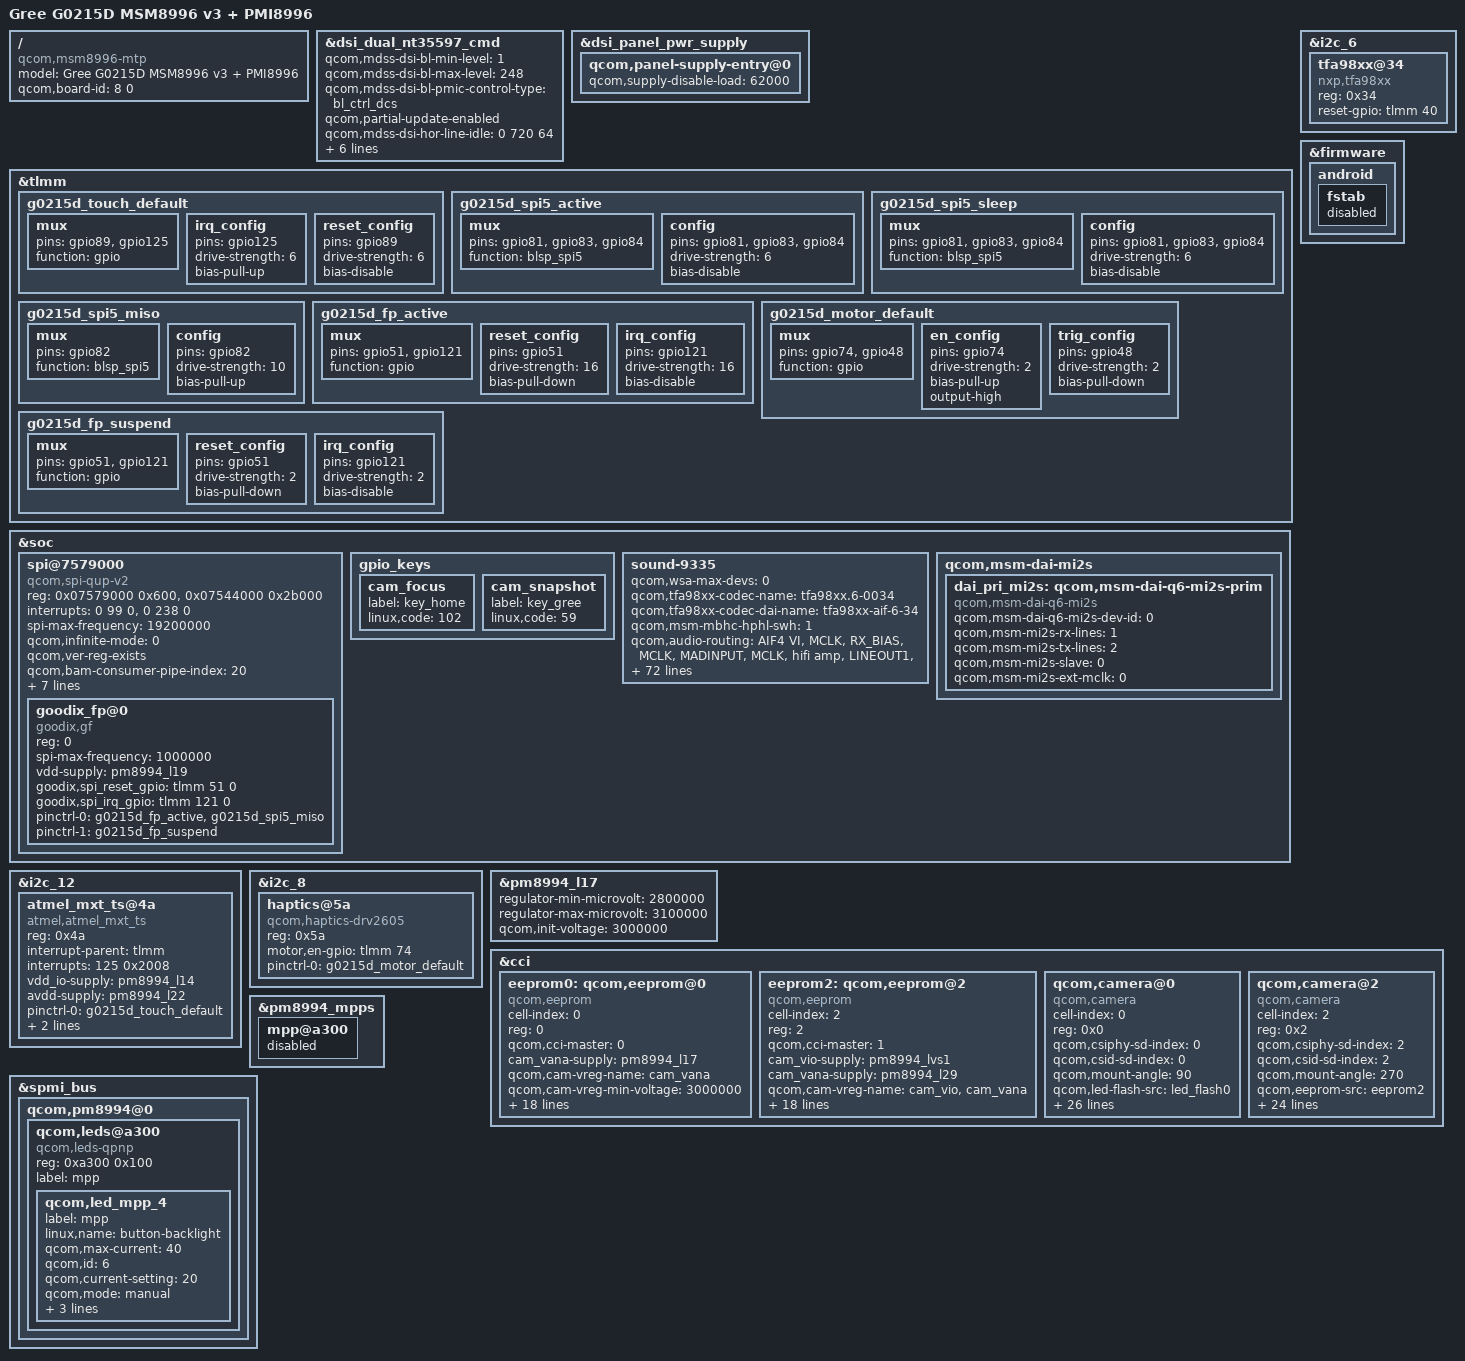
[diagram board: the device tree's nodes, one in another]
/* G0215D board. IDs match the bootloader on the running device:
 * msm-id 246 0x30001, board-id 8 0, pmic-id 0x20009 0x10013 0 0.
 * The bootloader appends the NT35597 config0 split_dsi panel selector.
 */

/dts-v1/;

#include "msm8996-v3.dtsi"
#include "msm-pmi8996.dtsi"
#include "msm8996-mtp.dtsi"

/ {
	model = "Gree G0215D MSM8996 v3 + PMI8996";
	compatible = "qcom,msm8996-mtp", "qcom,msm8996", "qcom,mtp";
	qcom,board-id = <8 0>;
};

&dsi_dual_nt35597_cmd {
	qcom,mdss-dsi-bl-min-level = <1>;
	qcom,mdss-dsi-bl-max-level = <248>;
	qcom,mdss-dsi-bl-pmic-control-type = "bl_ctrl_dcs";
	qcom,partial-update-enabled;
	/*
	 * 64 DSI byte-clocks of idle after each 720-wide line, and burst
	 * disabled. Command-mode burst was packing lines together; the
	 * dual-gate bands then crawl. 2A 0..719 did not change that.
	 */
	qcom,mdss-dsi-hor-line-idle = <0 720 64>;
	/*
	 * Autorefresh writes each pingpong on its own and skips CTL_START.
	 * Split display only starts both interfaces from the master's
	 * CTL_START, so leave autorefresh off.
	 */
	/*
	 * On-command runs on each controller in turn, including the 101 ms
	 * sleep-out wait. The right port would leave sleep a full command
	 * list later and the dual-gate locks to a different line. Broadcast
	 * sends each DCS byte to both ports from the same trigger.
	 */
	qcom,cmd-sync-wait-broadcast;
	/*
	 * One frame, not the 0xfff0 default. The read pointer has to wrap
	 * before the next transfer; 0xfff0 takes about 25 frames, so the
	 * next kickoff starts while the previous one is still on a random
	 * line.
	 */
	qcom,mdss-tear-check-sync-cfg-height = <2576>;
	/*
	 * Bootloader splash handoff skips the reset GPIO. fastboot has
	 * just programmed the panel, a reboot from recovery has not.
	 * Force the same GPIO reset and on-command on every boot.
	 * BTA during command-mode scanout leaves DSI0 CMD_DMA_BUSY.
	 */
	qcom,mdss-dsi-disable-cont-splash;
	/delete-property/ qcom,esd-check-enabled;
	/delete-property/ qcom,mdss-dsi-panel-status-check-mode;
	/*
	 * Display-off is 0x28 and tear-off is 0x34. With the link left in
	 * HS, those run while command-mode autorefresh still owns the DMA
	 * engine and time out (DSI status 0x7). LP sends them after the
	 * interface is stopped.
	 */
	qcom,mdss-dsi-off-command-state = "dsi_lp_mode";
	/* Factory payloads. Page 0x24 and 3B read back correctly on image 8.
	 * Do not send 28 ahead of this list. The factory sequence has none.
	 */
	qcom,mdss-dsi-on-command = [
		15 01 00 00 10 00 02 ff 10
		15 01 00 00 10 00 02 fb 01
		15 01 00 00 10 00 02 ba 03
		15 01 00 00 10 00 02 e5 01
		15 01 00 00 10 00 02 35 00
		15 01 00 00 10 00 02 bb 10
		15 01 00 00 10 00 02 b0 03
		39 01 00 00 10 00 06 3b 03 08 08 64 9a
		15 01 00 00 10 00 02 ff 20
		15 01 00 00 10 00 02 fb 01
		15 01 00 00 10 00 02 6d 88
		15 01 00 00 10 00 02 ff 24
		15 01 00 00 10 00 02 fb 01
		15 01 00 00 10 00 02 74 0c
		15 01 00 00 10 00 02 75 14
		15 01 00 00 10 00 02 7e 0c
		15 01 00 00 10 00 02 7f 14
		15 01 00 00 10 00 02 c6 07
		15 01 00 00 10 00 02 c8 10
		15 01 00 00 10 00 02 cf 33
		15 01 00 00 10 00 02 d0 01
		15 01 00 00 10 00 02 ff e0
		15 01 00 00 10 00 02 fb 01
		15 01 00 00 10 00 02 6b 3d
		15 01 00 00 10 00 02 6c 3d
		15 01 00 00 10 00 02 6d 3d
		15 01 00 00 10 00 02 6e 3d
		15 01 00 00 10 00 02 6f 3d
		15 01 00 00 10 00 02 35 02
		15 01 00 00 10 00 02 36 79
		15 01 00 00 10 00 02 37 10
		15 01 00 00 10 00 02 3f 0c
		15 01 00 00 10 00 02 08 c0
		15 01 00 00 10 00 02 ff 10
		05 01 00 00 65 00 02 11 00
		05 01 00 00 29 00 02 29 00
		15 01 00 00 10 00 02 53 2c
		15 01 00 00 10 00 02 55 01];
};

/*
 * pm8994_l14 is DSI vddio and the maXTouch vdd_io. The shared entry's
 * disable load of 80 uA puts that LDO in LPM while the touch controller
 * is still powered from it. A scan that finishes then resets the touch
 * chip; a stuck scan does not, which is why a clean picture and a dead
 * touch show up together.
 */
&dsi_panel_pwr_supply {
	qcom,panel-supply-entry@0 {
		qcom,supply-disable-load = <62000>;
	};
};

&tlmm {
	g0215d_touch_default: g0215d_touch_default {
		mux {
			pins = "gpio89", "gpio125";
			function = "gpio";
		};

		irq_config {
			pins = "gpio125";
			drive-strength = <6>;
			bias-pull-up;
		};

		reset_config {
			pins = "gpio89";
			drive-strength = <6>;
			bias-disable;
		};
	};

	g0215d_spi5_active: g0215d_spi5_active {
		mux {
			pins = "gpio81", "gpio83", "gpio84";
			function = "blsp_spi5";
		};

		config {
			pins = "gpio81", "gpio83", "gpio84";
			drive-strength = <6>;
			bias-disable;
		};
	};

	g0215d_spi5_sleep: g0215d_spi5_sleep {
		mux {
			pins = "gpio81", "gpio83", "gpio84";
			function = "blsp_spi5";
		};

		config {
			pins = "gpio81", "gpio83", "gpio84";
			drive-strength = <6>;
			bias-disable;
		};
	};

	g0215d_spi5_miso: g0215d_spi5_miso {
		mux {
			pins = "gpio82";
			function = "blsp_spi5";
		};

		config {
			pins = "gpio82";
			drive-strength = <10>;
			bias-pull-up;
		};
	};

	g0215d_fp_active: g0215d_fp_active {
		mux {
			pins = "gpio51", "gpio121";
			function = "gpio";
		};

		reset_config {
			pins = "gpio51";
			drive-strength = <16>;
			bias-pull-down;
		};

		irq_config {
			pins = "gpio121";
			drive-strength = <16>;
			bias-disable;
		};
	};

	/* Stock pmx_motor_active: GPIO 74 high enables the DRV2605.
	 * GPIO 48 is the trigger input and stays pulled down.
	 */
	g0215d_motor_default: g0215d_motor_default {
		mux {
			pins = "gpio74", "gpio48";
			function = "gpio";
		};

		en_config {
			pins = "gpio74";
			drive-strength = <2>;
			bias-pull-up;
			output-high;
		};

		trig_config {
			pins = "gpio48";
			drive-strength = <2>;
			bias-pull-down;
		};
	};

	g0215d_fp_suspend: g0215d_fp_suspend {
		mux {
			pins = "gpio51", "gpio121";
			function = "gpio";
		};

		reset_config {
			pins = "gpio51";
			drive-strength = <2>;
			bias-pull-down;
		};

		irq_config {
			pins = "gpio121";
			drive-strength = <2>;
			bias-disable;
		};
	};
};

/* Stock spi@7579000 (BLSP1 QUP5) carries the Goodix GF816M under the
 * front Home switch. The sensor also reads the two capacitive keys
 * beside it. Stock left BAM off on this bus. Reset is GPIO 51, IRQ is
 * GPIO 121, vdd is pm8994_l19 at 3.0V.
 */
&soc {
	spi@7579000 { /* BLSP1 QUP5 */
		compatible = "qcom,spi-qup-v2";
		#address-cells = <1>;
		#size-cells = <0>;
		reg-names = "spi_physical", "spi_bam_physical";
		reg = <0x07579000 0x600>,
		      <0x07544000 0x2b000>;
		interrupt-names = "spi_irq", "spi_bam_irq";
		interrupts = <0 99 0>, <0 238 0>;
		spi-max-frequency = <19200000>;
		qcom,infinite-mode = <0>;
		qcom,ver-reg-exists;
		qcom,bam-consumer-pipe-index = <20>;
		qcom,bam-producer-pipe-index = <21>;
		qcom,master-id = <86>;
		qcom,use-pinctrl;
		pinctrl-names = "spi_default", "spi_sleep";
		pinctrl-0 = <&g0215d_spi5_active>;
		pinctrl-1 = <&g0215d_spi5_sleep>;
		clock-names = "iface_clk", "core_clk";
		clocks = <&clock_gcc clk_gcc_blsp1_ahb_clk>,
			 <&clock_gcc clk_gcc_blsp1_qup5_spi_apps_clk>;

		goodix_fp@0 {
			compatible = "goodix,gf";
			reg = <0>;
			spi-max-frequency = <1000000>;
			vdd-supply = <&pm8994_l19>;
			goodix,spi_reset_gpio = <&tlmm 51 0>;
			goodix,spi_irq_gpio = <&tlmm 121 0>;
			pinctrl-names = "pmx_fp_active", "pmx_fp_suspend";
			pinctrl-0 = <&g0215d_fp_active &g0215d_spi5_miso>;
			pinctrl-1 = <&g0215d_fp_suspend>;
		};
	};
};

/* i2c12 is i2c@75ba000, so the device shows up as 12-004a.
 * Live touch_vdd is pm8994_l22 at 3.3V. vdd_io follows the LeEco
 * and MTP wiring to pm8994_l14 at 1.8V. No atmel,fw_version: the
 * ramdisk script loads A4_2F_4.0_05.fw and the OBP_RAW config.
 * T15 codes are the live touch_keyevent list.
 */
&i2c_12 {
	/delete-node/ synaptics@20;

	atmel_mxt_ts@4a {
		compatible = "atmel,atmel_mxt_ts";
		reg = <0x4a>;
		interrupt-parent = <&tlmm>;
		interrupts = <125 0x2008>;
		vdd_io-supply = <&pm8994_l14>;
		avdd-supply = <&pm8994_l22>;
		pinctrl-names = "default";
		pinctrl-0 = <&g0215d_touch_default>;
		atmel,reset-gpio = <&tlmm 89 0>;
		atmel,cap-button-codes = <139 172 158>;
	};
};

/* Stock gpio_keys: PM8994 GPIO 5 is the front Home switch (KEY_HOME),
 * GPIO 4 is the extra Gree key (KEY_F1). msm8996-mtp.dtsi still ships
 * the MTP camera-shutter codes (FOCUS 528 / CAMERA 766).
 */
&soc {
	gpio_keys {
		cam_focus {
			label = "key_home";
			linux,code = <102>;
		};

		cam_snapshot {
			label = "key_gree";
			linux,code = <59>;
		};
	};

	/* The speaker is one TFA9890 on quaternary MI2S. There are no
	 * WSA881x amplifiers; with wsa-max-devs > 0 the card defers forever.
	 */
	sound-9335 {
		qcom,wsa-max-devs = <0>;
		qcom,tfa98xx-codec-name = "tfa98xx.6-0034";
		qcom,tfa98xx-codec-dai-name = "tfa98xx-aif-6-34";
		/* No HDMI output; the ext-display codec is not built either. */
		/delete-property/ qcom,hdmi-audio-rx;
		/* Stock: the jack HPHL switch is normally closed. */
		qcom,msm-mbhc-hphl-swh = <1>;
		/* Stock: the handset mic (AMIC5) is biased by MIC BIAS4. */
		qcom,audio-routing =
			"AIF4 VI", "MCLK",
			"RX_BIAS", "MCLK",
			"MADINPUT", "MCLK",
			"hifi amp", "LINEOUT1",
			"hifi amp", "LINEOUT2",
			"AMIC2", "MIC BIAS2",
			"MIC BIAS2", "Headset Mic",
			"AMIC3", "MIC BIAS2",
			"MIC BIAS2", "ANCRight Headset Mic",
			"AMIC4", "MIC BIAS2",
			"MIC BIAS2", "ANCLeft Headset Mic",
			"AMIC5", "MIC BIAS4",
			"MIC BIAS4", "Handset Mic",
			"AMIC6", "MIC BIAS4",
			"MIC BIAS4", "Analog Mic6",
			"DMIC0", "MIC BIAS1",
			"MIC BIAS1", "Digital Mic0",
			"DMIC1", "MIC BIAS1",
			"MIC BIAS1", "Digital Mic1",
			"DMIC2", "MIC BIAS3",
			"MIC BIAS3", "Digital Mic2",
			"DMIC3", "MIC BIAS3",
			"MIC BIAS3", "Digital Mic3",
			"DMIC4", "MIC BIAS4",
			"MIC BIAS4", "Digital Mic4",
			"DMIC5", "MIC BIAS4",
			"MIC BIAS4", "Digital Mic5",
			"SpkrLeft IN", "SPK1 OUT",
			"SpkrRight IN", "SPK2 OUT";
		/* The machine driver links all four MI2S ports (primary to
		 * quaternary); the card defers if any of them is not listed.
		 */
		asoc-cpu = <&dai_pri_auxpcm>, <&dai_sec_auxpcm>,
				<&dai_hdmi>, <&dai_pri_mi2s>,
				<&dai_mi2s_sec>, <&dai_mi2s>, <&dai_mi2s_quat>,
				<&sb_0_rx>, <&sb_0_tx>,
				<&sb_1_rx>, <&sb_1_tx>,
				<&sb_2_rx>, <&sb_2_tx>,
				<&sb_3_rx>, <&sb_3_tx>,
				<&sb_4_rx>, <&sb_4_tx>,
				<&sb_5_tx>,
				<&afe_pcm_rx>, <&afe_pcm_tx>,
				<&afe_proxy_rx>, <&afe_proxy_tx>,
				<&incall_record_rx>, <&incall_record_tx>,
				<&incall_music_rx>, <&incall_music2_rx>,
				<&sb_5_rx>, <&sb_6_rx>,
				<&usb_audio_rx>, <&usb_audio_tx>,
				<&dai_pri_tdm_tx_0>, <&dai_pri_tdm_tx_1>,
				<&dai_pri_tdm_tx_2>, <&dai_pri_tdm_tx_3>,
				<&dai_pri_tdm_rx_0>, <&dai_pri_tdm_rx_1>,
				<&dai_pri_tdm_rx_2>, <&dai_pri_tdm_rx_3>,
				<&dai_sec_tdm_rx_0>, <&dai_sec_tdm_rx_1>,
				<&dai_sec_tdm_rx_2>, <&dai_sec_tdm_rx_3>,
				<&dai_sec_tdm_tx_0>, <&dai_sec_tdm_tx_1>,
				<&dai_sec_tdm_tx_2>, <&dai_sec_tdm_tx_3>,
				<&dai_tert_tdm_rx_0>, <&dai_tert_tdm_rx_1>,
				<&dai_tert_tdm_rx_2>, <&dai_tert_tdm_rx_3>,
				<&dai_tert_tdm_tx_0>, <&dai_tert_tdm_tx_1>,
				<&dai_tert_tdm_tx_2>, <&dai_tert_tdm_tx_3>,
				<&dai_quat_tdm_rx_0>, <&dai_quat_tdm_rx_1>,
				<&dai_quat_tdm_rx_2>, <&dai_quat_tdm_rx_3>,
				<&dai_quat_tdm_tx_0>, <&dai_quat_tdm_tx_1>,
				<&dai_quat_tdm_tx_2>, <&dai_quat_tdm_tx_3>;
		asoc-cpu-names = "msm-dai-q6-auxpcm.1", "msm-dai-q6-auxpcm.2",
				"msm-dai-q6-hdmi.8", "msm-dai-q6-mi2s.0",
				"msm-dai-q6-mi2s.1", "msm-dai-q6-mi2s.2",
				"msm-dai-q6-mi2s.3",
				"msm-dai-q6-dev.16384", "msm-dai-q6-dev.16385",
				"msm-dai-q6-dev.16386", "msm-dai-q6-dev.16387",
				"msm-dai-q6-dev.16388", "msm-dai-q6-dev.16389",
				"msm-dai-q6-dev.16390", "msm-dai-q6-dev.16391",
				"msm-dai-q6-dev.16392", "msm-dai-q6-dev.16393",
				"msm-dai-q6-dev.16395",
				"msm-dai-q6-dev.224", "msm-dai-q6-dev.225",
				"msm-dai-q6-dev.241", "msm-dai-q6-dev.240",
				"msm-dai-q6-dev.32771", "msm-dai-q6-dev.32772",
				"msm-dai-q6-dev.32773", "msm-dai-q6-dev.32770",
				"msm-dai-q6-dev.16394", "msm-dai-q6-dev.16396",
				"msm-dai-q6-dev.28672", "msm-dai-q6-dev.28673",
				"msm-dai-q6-tdm.36865", "msm-dai-q6-tdm.36867",
				"msm-dai-q6-tdm.36869", "msm-dai-q6-tdm.36871",
				"msm-dai-q6-tdm.36864", "msm-dai-q6-tdm.36866",
				"msm-dai-q6-tdm.36868", "msm-dai-q6-tdm.36870",
				"msm-dai-q6-tdm.36880", "msm-dai-q6-tdm.36882",
				"msm-dai-q6-tdm.36884", "msm-dai-q6-tdm.36886",
				"msm-dai-q6-tdm.36881", "msm-dai-q6-tdm.36883",
				"msm-dai-q6-tdm.36885", "msm-dai-q6-tdm.36887",
				"msm-dai-q6-tdm.36896", "msm-dai-q6-tdm.36898",
				"msm-dai-q6-tdm.36900", "msm-dai-q6-tdm.36902",
				"msm-dai-q6-tdm.36897", "msm-dai-q6-tdm.36899",
				"msm-dai-q6-tdm.36901", "msm-dai-q6-tdm.36903",
				"msm-dai-q6-tdm.36912", "msm-dai-q6-tdm.36914",
				"msm-dai-q6-tdm.36916", "msm-dai-q6-tdm.36918",
				"msm-dai-q6-tdm.36913", "msm-dai-q6-tdm.36915",
				"msm-dai-q6-tdm.36917", "msm-dai-q6-tdm.36919";
	};

	/* Stock has a primary MI2S DAI; the base msm8996.dtsi does not. */
	qcom,msm-dai-mi2s {
		dai_pri_mi2s: qcom,msm-dai-q6-mi2s-prim {
			compatible = "qcom,msm-dai-q6-mi2s";
			qcom,msm-dai-q6-mi2s-dev-id = <0>;
			qcom,msm-mi2s-rx-lines = <1>;
			qcom,msm-mi2s-tx-lines = <2>;
			qcom,msm-mi2s-slave = <0>;
			qcom,msm-mi2s-ext-mclk = <0>;
		};
	};
};

/* Stock i2c@757a000 (BLSP1 QUP6) also carries the TFA9890 speaker amp.
 * The driver matches the "tfa98xx" I2C id, so the stock compatible works.
 */
&i2c_6 {
	tfa98xx@34 {
		compatible = "nxp,tfa98xx";
		reg = <0x34>;
		reset-gpio = <&tlmm 40 0>;
	};
};

/* Stock i2c@75b6000 (BLSP2 QUP2) carries the DRV2605 at 0x5a.
 * The node name in the 3.18 dump is haptics-dev2605; the compatible
 * is qcom,haptics-drv2605. Enable is TLMM GPIO 74, active high.
 */
&i2c_8 {
	haptics@5a {
		compatible = "qcom,haptics-drv2605";
		reg = <0x5a>;
		motor,en-gpio = <&tlmm 74 0>;
		pinctrl-names = "default";
		pinctrl-0 = <&g0215d_motor_default>;
	};
};

/* Donor msm8996.dtsi publishes an AVB vendor fstab and a vbmeta chain
 * (vbmeta, dtbo, vendor). This GPT has none of those. First-stage init
 * prefers the DT fstab over the ramdisk one, then waits for the chain.
 * status disabled makes ReadFstabFromDt fail so /fstab.qcom is used.
 */
&firmware {
	android {
		fstab {
			status = "disabled";
		};
	};
};

/* Stock 3.18 camera nodes, from the running DTB dump. The MTP include
 * wires a reference rear/front pair (regulator VDIG/VIO, reset on
 * GPIO 26) that this board does not have. Rear S5K3P3 analog is
 * pm8994_l17 at 3.0V; its digital and IO rails are GPIOs. Front
 * OV8858 analog is pm8994_l29, IO is LVS1, digital is GPIO 21.
 */
&pm8994_l17 {
	regulator-min-microvolt = <2800000>;
	regulator-max-microvolt = <3100000>;
	qcom,init-voltage = <3000000>;
};

&cci {
	/delete-node/ qcom,camera@0;
	/delete-node/ qcom,camera@1;
	/delete-node/ qcom,camera@2;
	/delete-node/ qcom,eeprom@0;
	/delete-node/ qcom,eeprom@1;

	eeprom0: qcom,eeprom@0 {
		cell-index = <0>;
		reg = <0>;
		compatible = "qcom,eeprom";
		qcom,cci-master = <0>;
		cam_vana-supply = <&pm8994_l17>;
		qcom,cam-vreg-name = "cam_vana";
		qcom,cam-vreg-min-voltage = <3000000>;
		qcom,cam-vreg-max-voltage = <3000000>;
		qcom,cam-vreg-op-mode = <80000>;
		qcom,gpio-no-mux = <0>;
		pinctrl-names = "cam_default", "cam_suspend";
		pinctrl-0 = <&cam_sensor_mclk0_active &cam_sensor_rear_active>;
		pinctrl-1 = <&cam_sensor_mclk0_suspend &cam_sensor_rear_suspend>;
		gpios = <&tlmm 13 0>,
			<&tlmm 30 0>,
			<&tlmm 29 0>,
			<&tlmm 2 0>;
		qcom,gpio-standby = <1>;
		qcom,gpio-vdig = <2>;
		qcom,gpio-vio = <3>;
		qcom,gpio-req-tbl-num = <0 1 2 3>;
		qcom,gpio-req-tbl-flags = <1 0 0 0>;
		qcom,gpio-req-tbl-label = "CAMIF_MCLK0",
					  "CAM_STANDBY0",
					  "CAM_VDIG0",
					  "CAM_VIO0";
		clocks = <&clock_mmss clk_mclk0_clk_src>,
			<&clock_mmss clk_camss_mclk0_clk>;
		clock-names = "cam_src_clk", "cam_clk";
		qcom,clock-rates = <24000000 0>;
	};

	eeprom2: qcom,eeprom@2 {
		cell-index = <2>;
		reg = <2>;
		compatible = "qcom,eeprom";
		qcom,cci-master = <1>;
		cam_vio-supply = <&pm8994_lvs1>;
		cam_vana-supply = <&pm8994_l29>;
		qcom,cam-vreg-name = "cam_vio", "cam_vana";
		qcom,cam-vreg-min-voltage = <0 1000000>;
		qcom,cam-vreg-max-voltage = <0 2800000>;
		qcom,cam-vreg-op-mode = <0 80000>;
		qcom,gpio-no-mux = <0>;
		pinctrl-names = "cam_default", "cam_suspend";
		pinctrl-0 = <&cam_sensor_mclk2_active &cam_sensor_front_active>;
		pinctrl-1 = <&cam_sensor_mclk2_suspend &cam_sensor_front_suspend>;
		gpios = <&tlmm 15 0>,
			<&tlmm 23 0>,
			<&tlmm 21 0>;
		qcom,gpio-standby = <1>;
		qcom,gpio-vdig = <2>;
		qcom,gpio-req-tbl-num = <0 1 2>;
		qcom,gpio-req-tbl-flags = <1 0 0>;
		qcom,gpio-req-tbl-label = "CAMIF_MCLK1",
					  "CAM_STANDBY1",
					  "CAM_VDIG1";
		clocks = <&clock_mmss clk_mclk2_clk_src>,
			<&clock_mmss clk_camss_mclk2_clk>;
		clock-names = "cam_src_clk", "cam_clk";
		qcom,clock-rates = <24000000 0>;
	};

	qcom,camera@0 {
		cell-index = <0>;
		compatible = "qcom,camera";
		reg = <0x0>;
		qcom,csiphy-sd-index = <0>;
		qcom,csid-sd-index = <0>;
		qcom,mount-angle = <90>;
		qcom,led-flash-src = <&led_flash0>;
		qcom,actuator-src = <&actuator0>;
		qcom,eeprom-src = <&eeprom0>;
		cam_vana-supply = <&pm8994_l17>;
		qcom,cam-vreg-name = "cam_vana";
		qcom,cam-vreg-min-voltage = <3000000>;
		qcom,cam-vreg-max-voltage = <3000000>;
		qcom,cam-vreg-op-mode = <80000>;
		qcom,gpio-no-mux = <0>;
		pinctrl-names = "cam_default", "cam_suspend";
		pinctrl-0 = <&cam_sensor_mclk0_active &cam_sensor_rear_active>;
		pinctrl-1 = <&cam_sensor_mclk0_suspend &cam_sensor_rear_suspend>;
		gpios = <&tlmm 13 0>,
			<&tlmm 30 0>,
			<&tlmm 29 0>,
			<&tlmm 2 0>;
		qcom,gpio-standby = <1>;
		qcom,gpio-vdig = <2>;
		qcom,gpio-vio = <3>;
		qcom,gpio-req-tbl-num = <0 1 2 3>;
		qcom,gpio-req-tbl-flags = <1 0 0 0>;
		qcom,gpio-req-tbl-label = "CAMIF_MCLK0",
					  "CAM_STANDBY0",
					  "CAM_VDIG0",
					  "CAM_VIO0";
		qcom,sensor-position = <0>;
		qcom,sensor-mode = <0>;
		qcom,cci-master = <0>;
		status = "ok";
		clocks = <&clock_mmss clk_mclk0_clk_src>,
			<&clock_mmss clk_camss_mclk0_clk>;
		clock-names = "cam_src_clk", "cam_clk";
		qcom,clock-rates = <24000000 0>;
	};

	qcom,camera@2 {
		cell-index = <2>;
		compatible = "qcom,camera";
		reg = <0x2>;
		qcom,csiphy-sd-index = <2>;
		qcom,csid-sd-index = <2>;
		qcom,mount-angle = <270>;
		qcom,eeprom-src = <&eeprom2>;
		cam_vio-supply = <&pm8994_lvs1>;
		cam_vana-supply = <&pm8994_l29>;
		qcom,cam-vreg-name = "cam_vio", "cam_vana";
		qcom,cam-vreg-min-voltage = <0 1000000>;
		qcom,cam-vreg-max-voltage = <0 2800000>;
		qcom,cam-vreg-op-mode = <0 80000>;
		qcom,gpio-no-mux = <0>;
		pinctrl-names = "cam_default", "cam_suspend";
		pinctrl-0 = <&cam_sensor_mclk2_active &cam_sensor_front_active>;
		pinctrl-1 = <&cam_sensor_mclk2_suspend &cam_sensor_front_suspend>;
		gpios = <&tlmm 15 0>,
			<&tlmm 23 0>,
			<&tlmm 21 0>;
		qcom,gpio-standby = <1>;
		qcom,gpio-vdig = <2>;
		qcom,gpio-req-tbl-num = <0 1 2>;
		qcom,gpio-req-tbl-flags = <1 0 0>;
		qcom,gpio-req-tbl-label = "CAMIF_MCLK1",
					  "CAM_STANDBY1",
					  "CAM_VDIG1";
		qcom,sensor-position = <1>;
		qcom,sensor-mode = <0>;
		qcom,cci-master = <1>;
		status = "ok";
		clocks = <&clock_mmss clk_mclk2_clk_src>,
			<&clock_mmss clk_camss_mclk2_clk>;
		clock-names = "cam_src_clk", "cam_clk";
		qcom,clock-rates = <24000000 0>;
	};
};

/*
 * MTP enables PM8994 MPP4 as a digital HDMI 5V enable. This phone uses
 * that pin as the capacitive-key LED, the same current sink as the
 * factory tree (mpp@a300, 20 mA manual).
 */
&pm8994_mpps {
	mpp@a300 {
		status = "disabled";
	};
};

&spmi_bus {
	qcom,pm8994@0 {
		qcom,leds@a300 {
			compatible = "qcom,leds-qpnp";
			reg = <0xa300 0x100>;
			status = "okay";
			label = "mpp";

			qcom,led_mpp_4 {
				label = "mpp";
				linux,name = "button-backlight";
				qcom,max-current = <40>;
				qcom,id = <6>;
				qcom,current-setting = <20>;
				qcom,mode = "manual";
				qcom,mode-ctrl = <0x60>;
				qcom,source-sel = <1>;
				qcom,default-state = "off";
			};
		};
	};
};
